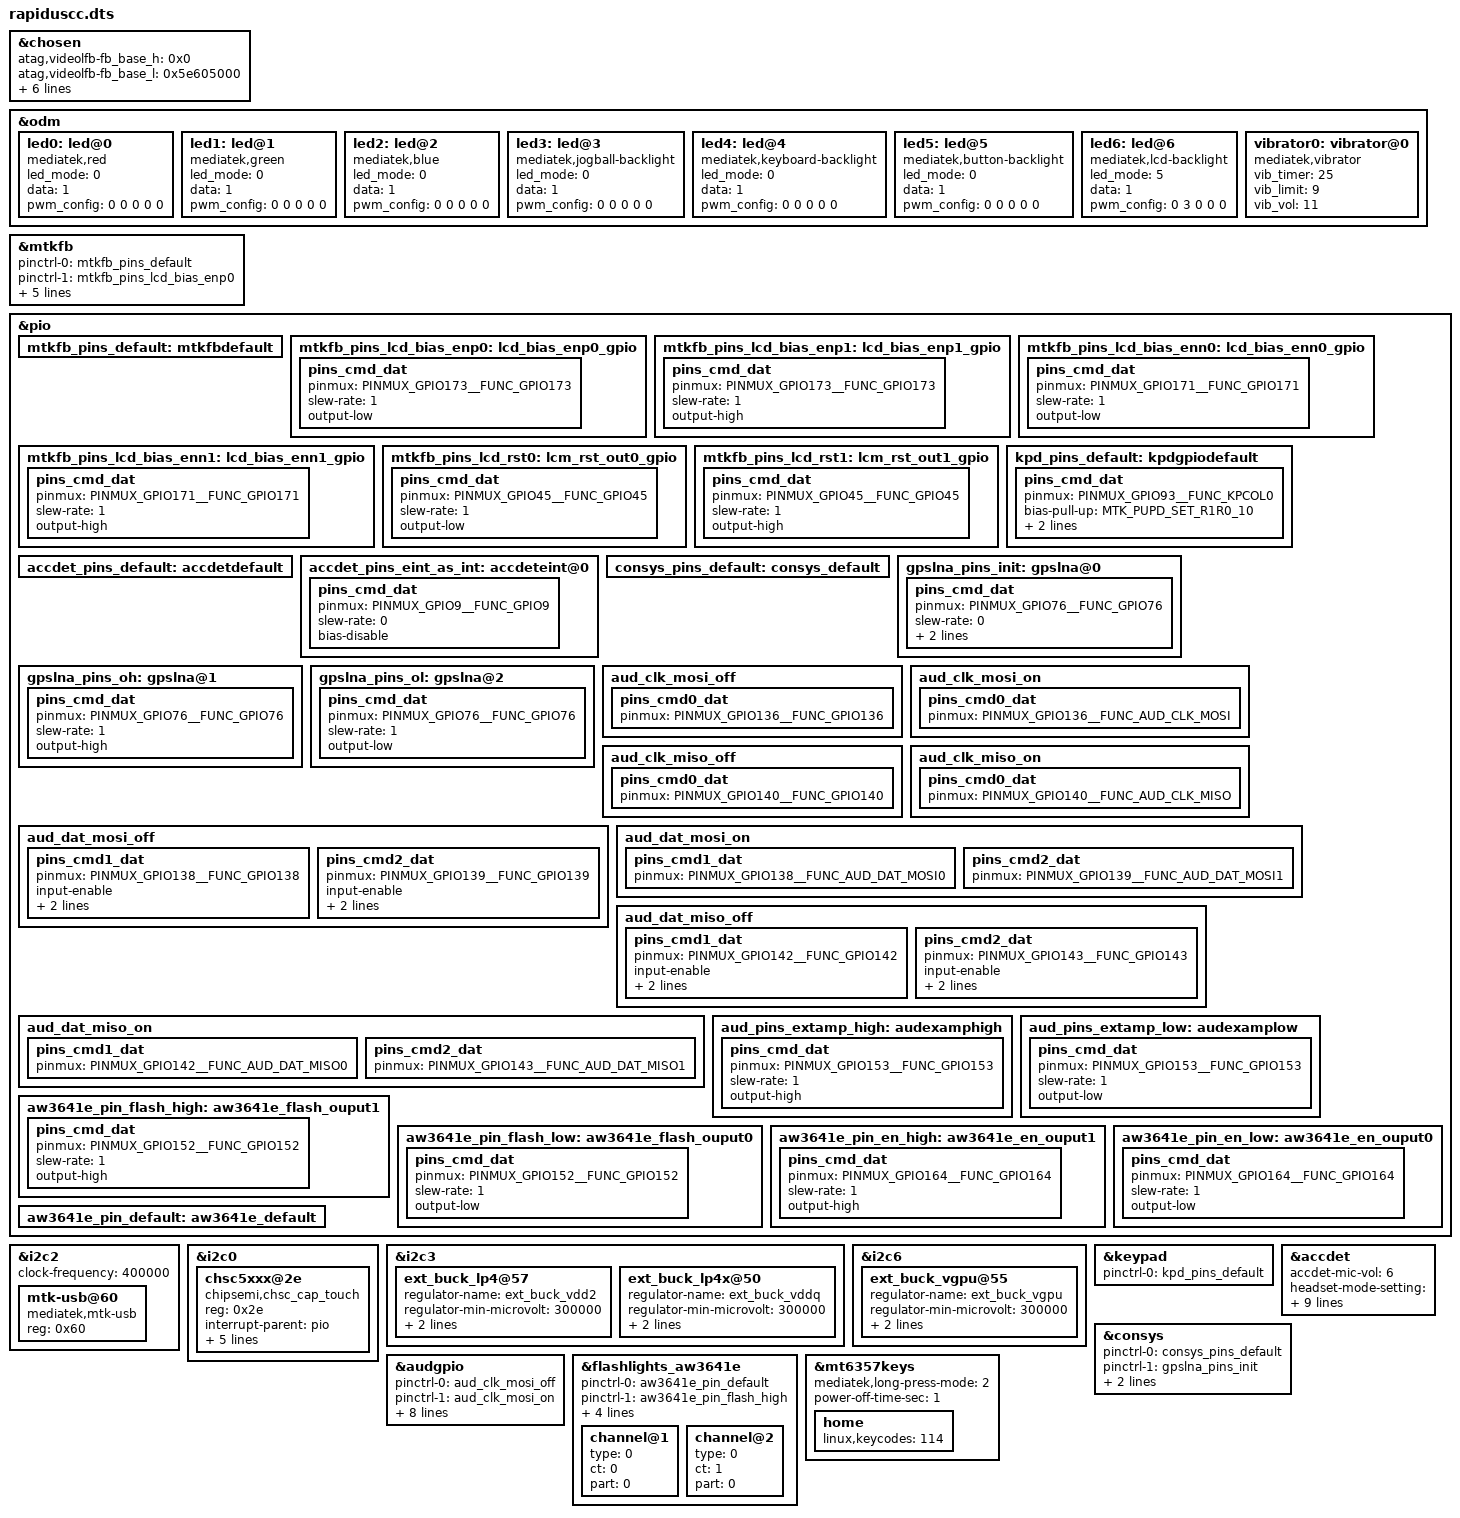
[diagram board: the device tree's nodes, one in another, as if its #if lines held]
// SPDX-License-Identifier: GPL-2.0+

#include <dt-bindings/interrupt-controller/arm-gic.h>
#include <dt-bindings/interrupt-controller/irq.h>
#include <dt-bindings/pinctrl/mt6761-pinfunc.h>
#include <dt-bindings/mmc/mt6761-msdc.h>
#include <dt-bindings/clock/mt6761-clk.h>

/dts-v1/;
/plugin/;

/* chosen */
&chosen {

	/* fpga may has no lk, we need to specify display info here */
	/* fb buffer is reserved using this dts by memory node above */
	atag,videolfb-fb_base_h = <0x0>;
	atag,videolfb-fb_base_l = <0x5e605000>;
	atag,videolfb-islcmfound = <1>;
	/* because no lk, so lcm is not inited */
	atag,videolfb-islcm_inited = <0>;
	atag,videolfb-fps= <6000>;
	atag,videolfb-vramSize= <0x017bb000>;
	atag,videolfb-lcmname= "nt35521_hd_dsi_vdo_truly_rt5081_drv";
};

&odm {
	led0:led@0 {
		compatible = "mediatek,red";
		led_mode = <0>;
		data = <1>;
		pwm_config = <0 0 0 0 0>;
	};
	led1:led@1 {
		compatible = "mediatek,green";
		led_mode = <0>;
		data = <1>;
		pwm_config = <0 0 0 0 0>;
	};
	led2:led@2 {
		compatible = "mediatek,blue";
		led_mode = <0>;
		data = <1>;
		pwm_config = <0 0 0 0 0>;
	};
	led3:led@3 {
		compatible = "mediatek,jogball-backlight";
		led_mode = <0>;
		data = <1>;
		pwm_config = <0 0 0 0 0>;
	};
	led4:led@4 {
		compatible = "mediatek,keyboard-backlight";
		led_mode = <0>;
		data = <1>;
		pwm_config = <0 0 0 0 0>;
	};
	led5:led@5 {
		compatible = "mediatek,button-backlight";
		led_mode = <0>;
		data = <1>;
		pwm_config = <0 0 0 0 0>;
	};
	led6:led@6 {
		compatible = "mediatek,lcd-backlight";
		led_mode = <5>;
		data = <1>;
		pwm_config = <0 3 0 0 0>;
	};
	vibrator0:vibrator@0 {
		compatible = "mediatek,vibrator";
		vib_timer = <25>;
		vib_limit = <9>;
		vib_vol= <11>;
	};
};

//begin add by xiongbo.huang for android r porting on 20200601
&mtkfb {
	pinctrl-names = "default", "lcd_bias_enp0_gpio", "lcd_bias_enp1_gpio","lcd_bias_enn0_gpio", "lcd_bias_enn1_gpio","lcm_rst_out0_gpio","lcm_rst_out1_gpio";
	pinctrl-0 = <&mtkfb_pins_default>;
	pinctrl-1 = <&mtkfb_pins_lcd_bias_enp0>;
	pinctrl-2 = <&mtkfb_pins_lcd_bias_enp1>;
	pinctrl-3 = <&mtkfb_pins_lcd_bias_enn0>;
	pinctrl-4 = <&mtkfb_pins_lcd_bias_enn1>;
	pinctrl-5 = <&mtkfb_pins_lcd_rst0>;
	pinctrl-6 = <&mtkfb_pins_lcd_rst1>;
	status = "okay";
};
&pio {
	mtkfb_pins_default: mtkfbdefault {
	};

	mtkfb_pins_lcd_bias_enp0: lcd_bias_enp0_gpio {
		pins_cmd_dat {
			pinmux = <PINMUX_GPIO173__FUNC_GPIO173>;
			slew-rate = <1>;
			output-low;
		};
	};

	mtkfb_pins_lcd_bias_enp1: lcd_bias_enp1_gpio {
		pins_cmd_dat {
			pinmux = <PINMUX_GPIO173__FUNC_GPIO173>;
			slew-rate = <1>;
			output-high;
		};
	};

	mtkfb_pins_lcd_bias_enn0: lcd_bias_enn0_gpio {
                   pins_cmd_dat {
                            pinmux = <PINMUX_GPIO171__FUNC_GPIO171>;
                            slew-rate = <1>;
                            output-low;
                   };
         };

         mtkfb_pins_lcd_bias_enn1: lcd_bias_enn1_gpio {
                   pins_cmd_dat {
                            pinmux = <PINMUX_GPIO171__FUNC_GPIO171>;
                            slew-rate = <1>;
                            output-high;
                   };
         };

         mtkfb_pins_lcd_rst0: lcm_rst_out0_gpio {
                   pins_cmd_dat {
                            pinmux = <PINMUX_GPIO45__FUNC_GPIO45>;
                            slew-rate = <1>;
                            output-low;
                   };
         };

         mtkfb_pins_lcd_rst1: lcm_rst_out1_gpio {
                   pins_cmd_dat {
                            pinmux = <PINMUX_GPIO45__FUNC_GPIO45>;
                            slew-rate = <1>;
                            output-high;
                   };
         };

};

//end add by xiongbo.huang for android r porting on 20200601


&i2c2 {
	#address-cells = <1>;
	#size-cells = <0>;
	clock-frequency = <400000>;

	mtk-usb@60 {
		compatible = "mediatek,mtk-usb";
		reg = <0x60>;
		status = "okay";
	};
};

&i2c0 {
	//Begin add by bing-zhang for RATF-425 on 2022/01/05
	chsc5xxx@2e{
		status = "okay";
		compatible = "chipsemi,chsc_cap_touch";
		reg = <0x2e>;
		interrupt-parent = <&pio>;
		interrupts = <0 IRQ_TYPE_EDGE_FALLING 0 0>;
		vdd-supply = <&mt_pmic_vldo28_ldo_reg>;
		vio-supply = <&mt_pmic_vio18_ldo_reg>;
		chipsemi,int-gpio = <&pio 0 0>;
		chipsemi,rst-gpio = <&pio 46 0>;
	};
	//End add by bing-zhang for RATF-425 on 2022/01/05
};

&i2c3 {
	ext_buck_lp4@57 {
		regulator-name ="ext_buck_vdd2";
		regulator-min-microvolt = <300000>;
		regulator-max-microvolt = <1300000>;
		vsel_pin = <0>;
	};

	ext_buck_lp4x@50 {
		regulator-name ="ext_buck_vddq";
		regulator-min-microvolt = <300000>;
		regulator-max-microvolt = <1300000>;
		vsel_pin = <1>;
	};
};

&i2c6 {
	ext_buck_vgpu@55 {
		regulator-name ="ext_buck_vgpu";
		regulator-min-microvolt = <300000>;
		regulator-max-microvolt = <1300000>;
		vsel_pin = <2>;
	};
};

&keypad {
	pinctrl-names = "default";
	pinctrl-0 = <&kpd_pins_default>;
};

&pio {
	kpd_pins_default: kpdgpiodefault {
		pins_cmd_dat {
			pinmux = <PINMUX_GPIO93__FUNC_KPCOL0>;
			bias-pull-up = <MTK_PUPD_SET_R1R0_10>;
			output-low;
			input-schmitt-enable;
		};
	};
};


/* accdet start */
&accdet {
	/* accdet micbias voltage: 0x07,2.7v;0x05,2.5v;0x02,1.9v */
	accdet-mic-vol = <6>;
	headset-mode-setting = <0x500 0x500 1 0x1f0 0x2000 0x800 0x20 0x44>;
	accdet-plugout-debounce = <20>;
	/*1:ACC mode, 2:low cost without in bias, 6:low cost with in bias*/
	accdet-mic-mode = <1>;
	headset-eint-level-pol = <8>;
	headset-three-key-threshold = <0 80 220 400>;
	headset-three-key-threshold-CDD = <0 121 192 600>;
	headset-four-key-threshold = <0 58 121 192 400>;
	pinctrl-names = "default", "state_eint_as_int";
	pinctrl-0 = <&accdet_pins_default>;
	pinctrl-1 = <&accdet_pins_eint_as_int>;
	status = "okay";
};
&pio {
	accdet_pins_default: accdetdefault {
	};
	accdet_pins_eint_as_int: accdeteint@0 {
		pins_cmd_dat {
			pinmux = <PINMUX_GPIO9__FUNC_GPIO9>;
			slew-rate = <0>;
			bias-disable;
		};
	};
};

/* CONSYS GPIO standardization */
&pio {
	consys_pins_default: consys_default {
	};
	gpslna_pins_init: gpslna@0 {
		pins_cmd_dat {
			pinmux = <PINMUX_GPIO76__FUNC_GPIO76>;
			slew-rate = <0>;
			bias-disable;
			output-low;
		};
	};
	gpslna_pins_oh: gpslna@1 {
		pins_cmd_dat {
			pinmux = <PINMUX_GPIO76__FUNC_GPIO76>;
			slew-rate = <1>;
			output-high;
		};
	};
	gpslna_pins_ol: gpslna@2 {
		pins_cmd_dat {
			pinmux = <PINMUX_GPIO76__FUNC_GPIO76>;
			slew-rate = <1>;
			output-low;
		};
	};
};
&consys {
	pinctrl-names = "default", "gps_lna_state_init",
		"gps_lna_state_oh", "gps_lna_state_ol";
	pinctrl-0 = <&consys_pins_default>;
	pinctrl-1 = <&gpslna_pins_init>;
	pinctrl-2 = <&gpslna_pins_oh>;
	pinctrl-3 = <&gpslna_pins_ol>;
	status = "okay";
};
/* CONSYS end */

/* AUDIO GPIO standardization */
&audgpio {
	pinctrl-names = "aud_clk_mosi_off",
			"aud_clk_mosi_on",
			"aud_clk_miso_off",
			"aud_clk_miso_on",
			"aud_dat_mosi_off",
			"aud_dat_mosi_on",
			"aud_dat_miso_off",
			"aud_dat_miso_on",
			"extamp-pullhigh",
			"extamp-pulllow";

	pinctrl-0 = <&aud_clk_mosi_off>;
	pinctrl-1 = <&aud_clk_mosi_on>;
	pinctrl-2 = <&aud_clk_miso_off>;
	pinctrl-3 = <&aud_clk_miso_on>;
	pinctrl-4 = <&aud_dat_mosi_off>;
	pinctrl-5 = <&aud_dat_mosi_on>;
	pinctrl-6 = <&aud_dat_miso_off>;
	pinctrl-7 = <&aud_dat_miso_on>;
	pinctrl-8 = <&aud_pins_extamp_high>;
	pinctrl-9 = <&aud_pins_extamp_low>;
	status = "okay";
};

&pio {
	aud_clk_mosi_off: aud_clk_mosi_off {
		pins_cmd0_dat {
			pinmux = <PINMUX_GPIO136__FUNC_GPIO136>;
		};
	};

	aud_clk_mosi_on: aud_clk_mosi_on {
		pins_cmd0_dat {
			pinmux = <PINMUX_GPIO136__FUNC_AUD_CLK_MOSI>;
		};
	};

	aud_clk_miso_off: aud_clk_miso_off {
		pins_cmd0_dat {
			pinmux = <PINMUX_GPIO140__FUNC_GPIO140>;
		};
	};

	aud_clk_miso_on: aud_clk_miso_on {
		pins_cmd0_dat {
			pinmux = <PINMUX_GPIO140__FUNC_AUD_CLK_MISO>;
		};
	};

	aud_dat_mosi_off: aud_dat_mosi_off {
		pins_cmd1_dat {
			pinmux = <PINMUX_GPIO138__FUNC_GPIO138>;
			input-enable;
			slew-rate = <0>;
			bias-disable;
		};
		pins_cmd2_dat {
			pinmux = <PINMUX_GPIO139__FUNC_GPIO139>;
			input-enable;
			slew-rate = <0>;
			bias-disable;
		};
	};

	aud_dat_mosi_on: aud_dat_mosi_on {
		pins_cmd1_dat {
			pinmux = <PINMUX_GPIO138__FUNC_AUD_DAT_MOSI0>;
		};
		pins_cmd2_dat {
			pinmux = <PINMUX_GPIO139__FUNC_AUD_DAT_MOSI1>;
		};
	};

	aud_dat_miso_off: aud_dat_miso_off {
		pins_cmd1_dat {
			pinmux = <PINMUX_GPIO142__FUNC_GPIO142>;
			input-enable;
			slew-rate = <0>;
			bias-disable;
		};
		pins_cmd2_dat {
			pinmux = <PINMUX_GPIO143__FUNC_GPIO143>;
			input-enable;
			slew-rate = <0>;
			bias-disable;
		};
	};

	aud_dat_miso_on: aud_dat_miso_on {
		pins_cmd1_dat {
			pinmux = <PINMUX_GPIO142__FUNC_AUD_DAT_MISO0>;
		};
		pins_cmd2_dat {
			pinmux = <PINMUX_GPIO143__FUNC_AUD_DAT_MISO1>;
		};
	};

	aud_pins_extamp_high: audexamphigh {
		pins_cmd_dat {
			pinmux = <PINMUX_GPIO153__FUNC_GPIO153>;
			slew-rate = <1>;
			output-high;
		};
	};

	aud_pins_extamp_low: audexamplow {
		pins_cmd_dat {
			pinmux = <PINMUX_GPIO153__FUNC_GPIO153>;
			slew-rate = <1>;
			output-low;
		};
	};

};
/* AUDIO end */
/*Begin 20220118 junyiliu add for rapidtf flashlight porting*/
&pio {
	aw3641e_pin_flash_high: aw3641e_flash_ouput1 {
		pins_cmd_dat {
			pinmux = <PINMUX_GPIO152__FUNC_GPIO152>;
			slew-rate = <1>;
			output-high;
		};
	};
	aw3641e_pin_flash_low: aw3641e_flash_ouput0 {
		pins_cmd_dat {
			pinmux = <PINMUX_GPIO152__FUNC_GPIO152>;
			slew-rate = <1>;
			output-low;
		};
	};
	aw3641e_pin_en_high: aw3641e_en_ouput1 {
		pins_cmd_dat {
			pinmux = <PINMUX_GPIO164__FUNC_GPIO164>;
			slew-rate = <1>;
			output-high;
		};
	};
	aw3641e_pin_en_low: aw3641e_en_ouput0 {
		pins_cmd_dat {
			pinmux = <PINMUX_GPIO164__FUNC_GPIO164>;
			slew-rate = <1>;
			output-low;
		};
	};
	aw3641e_pin_default: aw3641e_default {
	};

};
 
&flashlights_aw3641e {
	pinctrl-names = "default", "flash_high", "flash_low", "en_high", "en_low";
	pinctrl-0 = <&aw3641e_pin_default>;
	pinctrl-1 = <&aw3641e_pin_flash_high>;
	pinctrl-2 = <&aw3641e_pin_flash_low>;
	pinctrl-3 = <&aw3641e_pin_en_high>;
	pinctrl-4 = <&aw3641e_pin_en_low>;
	status = "okay";
	decouple = <0>;
	channel@1 {
		type = <0>;
		ct = <0>;
		part = <0>;
	};
	channel@2 {
		type = <0>;
		ct = <1>;
		part = <0>;
	};
};
/*Begin 20220118 junyiliu add for rapidtf flashlight porting*/
/* Begin added by qiaozhen.li for task-11468129 20210901 */
&mt6357keys{
#if defined(TARGET_BUILD_MMITEST) || defined(TARGET_BUILD_CERTIFICATION) || defined(TARGET_BUILD_GCF) || defined(TARGET_BUILD_ENDURANCE)
    mediatek,long-press-mode = <2>;
#else
    mediatek,long-press-mode = <1>;
#endif
    power-off-time-sec = <1>;//11s
    home {
        linux,keycodes = <114>;
    };
};
/* End added by qiaozhen.li for task-11468129 20210901 */

#include "mediatek/jettaatt_61_charge.dtsi"
#include "mediatek/bat_setting/jetta_att/Jetta_att_mt6765_battery_prop_ext.dtsi"
#include <rapiduscc/cust.dtsi>
#include "mediatek/cust_mt6761_camera_rapiduscc.dtsi" //junyiliu modify for rapidckt camera
/*#include "mediatek/cust_mt6761_touch_jetta_720x1560.dtsi"*/
/*End of this file, DO NOT ADD ANYTHING HERE*/
